# MM32F103xx register map
File version: 1.08
Registers are 32-bit, read-write, reset 0x0 unless marked. A register's access mark holds for its fields unless they carry their own. Offsets are from the block's base; [hi:lo] are bit positions; {n}, {i} and the like mark numbered series.

## AES — Advanced Encryption Standard
Base 0x40026000
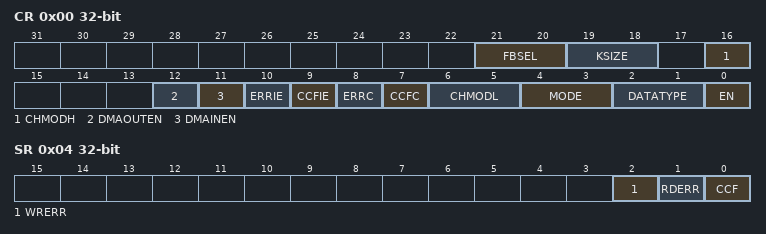
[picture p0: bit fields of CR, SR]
0x00 CR
  [21:20] FBSEL — Feedback selection
  [19:18] KSIZE — Key size
  [16] CHMODH — AES chaining mode high bits
  [12] DMAOUTEN — DMA Enable managing the data output phase
  [11] DMAINEN — DMA Enable managing the data input phase
  [10] ERRIE — Error Interrupt Enable
  [9] CCFIE — Computation Complete Interrupt Enable
  [8] ERRC — Error Clear
  [7] CCFC — Computation Complete Flag Clear
  [6:5] CHMODL — AES chaining mode low bits
  [4:3] MODE — AES mode Of operation
  [2:1] DATATYPE — Data type selection
  [0] EN — AES enable
0x04 SR
  [2] WRERR — Write Error Flag
  [1] RDERR — Read Error Flag
  [0] CCF — Computation Complete Flag
0x08 DINR
  [31:0] DINR — AES Data Input Register
0x0C DOUTR
  [31:0] DOUTR — AES Data Output Register
{0x10+4i} KEYR{i} (i=0..3)
  [31:0] KEYR{i} — AES Key Register {i}
{0x20+4i} IVR{i} (i=0..3)
  [31:0] IVR{i} — AES initialization vector register {i}
{0x20+4i} KEYR{i} (i=4..7)
  [31:0] KEYR{i} — AES Key Register {i}

## AFIO — Alternate function I/O
Base 0x40010000
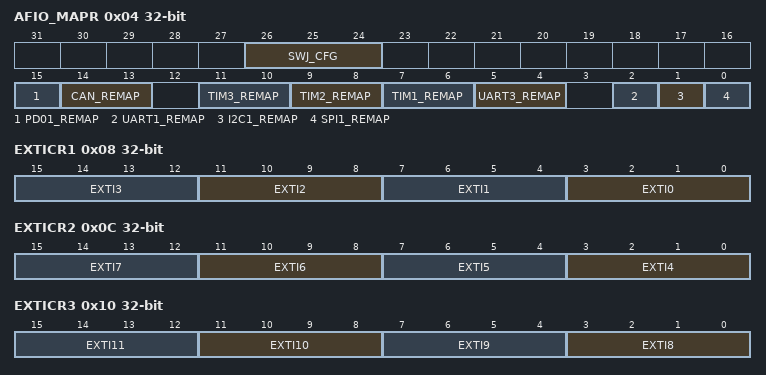
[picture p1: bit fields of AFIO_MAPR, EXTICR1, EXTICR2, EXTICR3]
0x04 AFIO_MAPR — Multiplexed remapping and debug I/O configuration registers
  [26:24] SWJ_CFG — Serial wire JTAG configuration
  [15] PD01_REMAP — Port D0/Port D1 mapping on OSC_IN/OSC_OUT
  [14:13] CAN_REMAP — CAN alternate function remapping
  [11:10] TIM3_REMAP — TIM3 remapping
  [9:8] TIM2_REMAP — TIM2 remapping
  [7:6] TIM1_REMAP — TIM1 remapping
  [5:4] UART3_REMAP — UART 3 remapping
  [2] UART1_REMAP — UART 1 remapping
  [1] I2C1_REMAP — I2C 1 remapping
  [0] SPI1_REMAP — SPI 1 remapping
0x08 EXTICR1 — Peripheral interrupt configuration register1
  [4n+3:4n] EXTI{n} (n=0..3) — EXTI{n} configuration
0x0C EXTICR2 — Peripheral interrupt configuration register2
  [4n-13:4n-16] EXTI{n} (n=4..7) — EXTI{n} configuration
0x10 EXTICR3 — Peripheral interrupt configuration register3
  [4n-29:4n-32] EXTI{n} (n=8..11) — EXTI{n} configuration
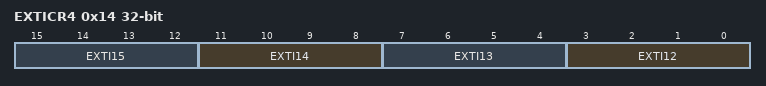
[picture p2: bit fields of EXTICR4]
0x14 EXTICR4 — Peripheral interrupt configuration register4
  [4n-45:4n-48] EXTI{n} (n=12..15) — EXTI{n} configuration

## BKP — Backup registers
Base 0x40006C00
{0x0+4i} DR{i} (i=1..10) — Backup data register(BKP_DR)
  [15:0] D — Backup data
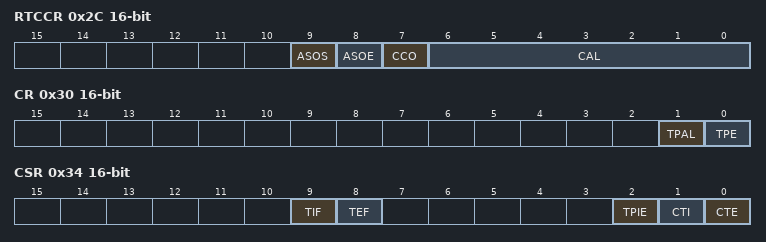
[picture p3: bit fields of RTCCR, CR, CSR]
0x2C RTCCR 16-bit — RTC clock calibration register
  [9] ASOS — Alarm or second output selection
  [8] ASOE — Alarm or second output enable
  [7] CCO — Calibration clock output
  [6:0] CAL — Calibration value
0x30 CR 16-bit — Backup control register
  [1] TPAL — TAMPER pin active level
  [0] TPE — TAMPER pin enable
0x34 CSR 16-bit — BKP control/status register
  [9] TIF — Tamper interrupt flag
  [8] TEF — Tamper event flag
  [2] TPIE — TAMPER pin interrupt enable
  [1] CTI — Clear tamper interrupt
  [0] CTE — Clear tamper event

## CAN — Controller area network
Base 0x40006400
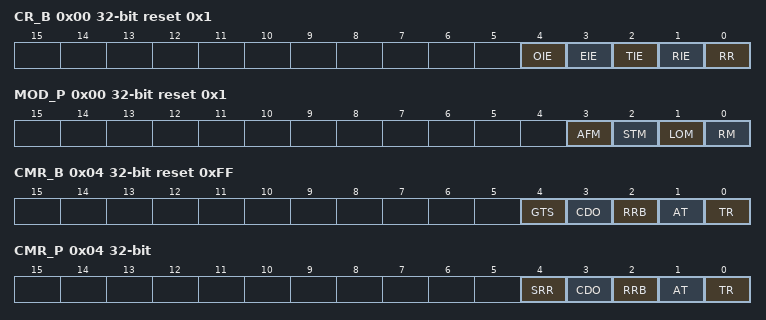
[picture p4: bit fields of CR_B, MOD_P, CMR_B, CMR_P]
0x00 CR_B reset 0x1
  [4] OIE — Overflow interrupt enable
  [3] EIE — Error interrupt enable
  [2] TIE — Transmit interrupt enable
  [1] RIE — Receive interrupt enable
  [0] RR — Reset request
0x00 MOD_P reset 0x1 (alternate view of CR_B)
  [3] AFM — Acceptance filter mode
  [2] STM — Self test mode
  [1] LOM — Listen only mode
  [0] RM — Reset mode
0x04 CMR_B wo reset 0xFF
  [4] GTS — Go to sleep
  [3] CDO — Clear data overrun
  [2] RRB — Release receive buffer
  [1] AT — Abort transmission
  [0] TR — Transmission request
0x04 CMR_P wo (alternate view of CMR_B)
  [4] SRR — Self reset request
  [3] CDO — Clear data overrun
  [2] RRB — Release receive buffer
  [1] AT — Abort transmission
  [0] TR — Transmission request
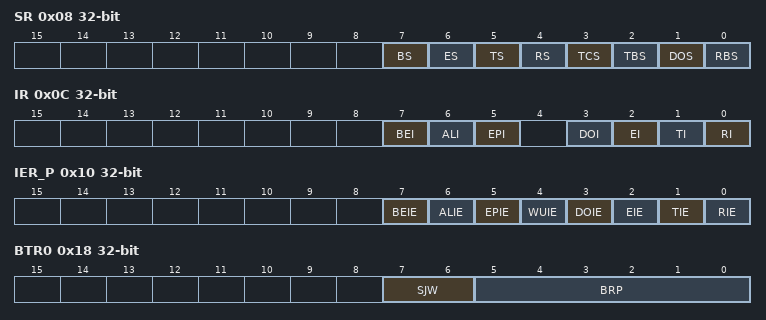
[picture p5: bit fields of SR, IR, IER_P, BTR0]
0x08 SR
  [7] BS — Bus status
  [6] ES — Error status
  [5] TS — Transmit status
  [4] RS — Receive status
  [3] TCS — Transmission complete status
  [2] TBS — Transmit buffer status
  [1] DOS — Data overrun status
  [0] RBS — Receive buffer status
0x0C IR ro
  [7] BEI
  [6] ALI
  [5] EPI
  [3] DOI — Data overrun interrupt
  [2] EI — Error interrupt
  [1] TI — Transmit interrupt
  [0] RI — Receive interrupt
0x10 ACR_B
  [7:0] AC — Acceptance code
0x10 IER_P (alternate view of ACR_B)
  [7] BEIE — Bus error interrupt enable
  [6] ALIE — Arbitration lost interrupt enable
  [5] EPIE — Error passive interrupt enable
  [4] WUIE — Wake up interrupt enable
  [3] DOIE — Data overrun interrupt enable
  [2] EIE — Error interrupt enable
  [1] TIE — Transmit interrupt enable
  [0] RIE — Receive interrupt enable
0x14 AMR_B
  [7:0] AM — Acceptance mask
0x18 BTR0
  [7:6] SJW — Synchronization jump width
  [5:0] BRP — Baud rate prescaler
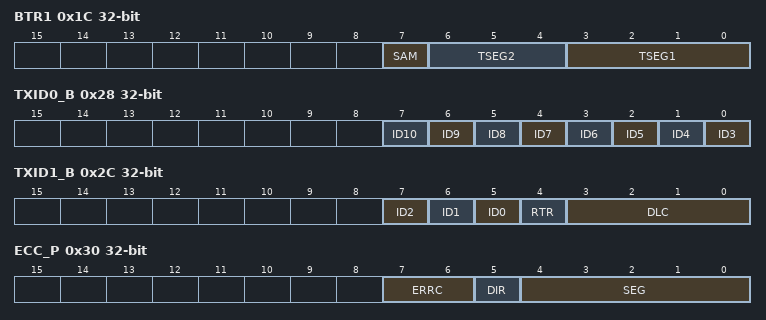
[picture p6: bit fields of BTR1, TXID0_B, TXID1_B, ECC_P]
0x1C BTR1
  [7] SAM — Sampling
  [6:4] TSEG2 — Time segment 2
  [3:0] TSEG1 — Time segment 1
0x28 TXID0_B
  [n-3] ID{n} (n=3..10) — Identifier bit {n}
0x2C TXID1_B
  [7] ID2 — Identifier bit 2
  [6] ID1 — Identifier bit 1
  [5] ID0 — Identifier bit 0
  [4] RTR — Remote transmission request
  [3:0] DLC — Data length code
0x2C ALC_P (alternate view of TXID1_B)
  [4:0] BITNO — Bit number
{0x30+4i} TXDR{i}_B (i=0..7)
  [31:0] TXDR{i} — Transmit data register
0x30 ECC_P ro (alternate view of TXDR0_B)
  [7:6] ERRC — Error code
  [5] DIR — Direction
  [4:0] SEG
0x34 EWLR_P reset 0x96 (alternate view of TXDR1_B)
  [7:0] EWL — Programmable error warning limit
0x38 RXERR_P (alternate view of TXDR2_B)
  [7:0] RXERR — RX error counter register
0x3C TXERR_P (alternate view of TXDR3_B)
  [7:0] TXERR — TX error counter register
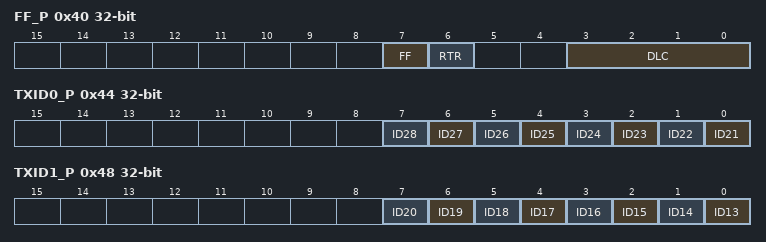
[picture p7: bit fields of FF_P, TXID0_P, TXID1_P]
0x40 FF_P (alternate view of TXDR4_B)
  [7] FF — Frame format
  [6] RTR — Remote transmission request
  [3:0] DLC — Data length code bit
0x40 ACR0_P (alternate view of FF_P)
  [7:0] AC — Acceptance code
0x44 TXID0_P (alternate view of TXDR5_B)
  [n-21] ID{n} (n=21..28) — Identifier bit {n}
0x44 ACR1_P (alternate view of TXID0_P)
  [7:0] AC — Acceptance code
0x48 TXID1_P (alternate view of TXDR6_B)
  [n-13] ID{n} (n=13..20) — Identifier bit {n}
0x48 ACR2_P (alternate view of TXID1_P)
  [7:0] AC — Acceptance code
0x4C TXDATA0_P (alternate view of TXDR7_B)
  [7:0] DATA0
0x4C ACR3_P (alternate view of TXDATA0_P)
  [7:0] AC — Acceptance code
{0x4C+4i} TXDATA{i}_P (i=1..9)
  [7:0] DATA{i}
{0x50+4i} AMR{i}_P (alternate view of TXDATA{i+1}_P) (i=0..3)
  [7:0] AM — Acceptance mask
0x7C CDR
  [7] MODE — CAN mode
